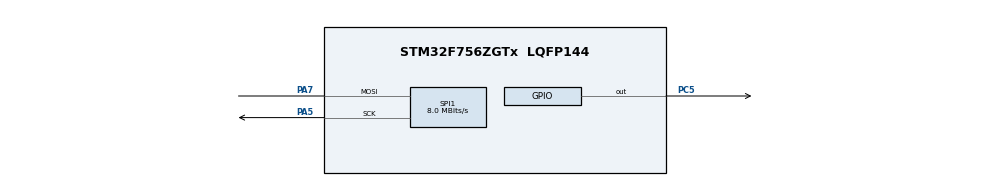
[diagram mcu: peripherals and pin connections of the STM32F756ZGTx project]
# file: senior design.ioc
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CORTEX_M7.default_mode_Activation=1
Mcu.Family=STM32F7
Mcu.Name=STM32F756ZGTx
Mcu.Package=LQFP144
NVIC.PriorityGroup=NVIC_PRIORITYGROUP_4
PA5.Mode=Simplex_Bidirectional_Master
PA5.Signal=SPI1_SCK
PA7.Mode=Simplex_Bidirectional_Master
PA7.Signal=SPI1_MOSI
PC5.Signal=GPIO_Output
ProjectManager.HeapSize=0x200
ProjectManager.StackSize=0x400
ProjectManager.TargetToolchain=STM32CubeIDE
RCC.HSE_VALUE=25000000
RCC.HSI_VALUE=16000000
RCC.LSE_VALUE=32768
RCC.USBFreq_Value=96000000
RCC.VCOOutputFreq_Value=192000000
SPI1.CalculateBaudRate=8.0 MBits/s
SPI1.Direction=SPI_DIRECTION_1LINE
SPI1.Mode=SPI_MODE_MASTER
SPI1.VirtualType=VM_MASTER
board=custom

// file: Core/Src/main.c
/* USER CODE BEGIN Header */
/**
  ******************************************************************************
  * @file           : main.c
  * @brief          : Main program body
  ******************************************************************************
  * @attention
  *
  * Copyright (c) 2025 STMicroelectronics.
  * All rights reserved.
  *
  * This software is licensed under terms that can be found in the LICENSE file
  * in the root directory of this software component.
  * If no LICENSE file comes with this software, it is provided AS-IS.
  *
  ******************************************************************************
  */
/* USER CODE END Header */
#include "main.h"

SPI_HandleTypeDef hspi1;

void SystemClock_Config(void);
static void MPU_Config(void);
static void MX_GPIO_Init(void);
static void MX_SPI1_Init(void);

int main(void)
{

  /* MPU Configuration--------------------------------------------------------*/
  MPU_Config();

  /* MCU Configuration--------------------------------------------------------*/

  /* Reset of all peripherals, Initializes the Flash interface and the Systick. */
  HAL_Init();

  /* Configure the system clock */
  SystemClock_Config();

  /* Initialize all configured peripherals */
  MX_GPIO_Init();
  MX_SPI1_Init();

  /* Infinite loop */
  /* USER CODE BEGIN WHILE */
  HAL_GPIO_WritePin(GPIOC, GPIO_PIN_5, GPIO_PIN_RESET);  // CS low
  HAL_Delay(1);  // wait 1 ms for OLED power to stabilize

   uint16_t cmd;

   // Function Set: 0x38
   cmd = 0x038;
   HAL_GPIO_WritePin(GPIOC, GPIO_PIN_5, GPIO_PIN_RESET);
   HAL_SPI_Transmit(&hspi1, (uint8_t *)&cmd, 1, HAL_MAX_DELAY);
   HAL_GPIO_WritePin(GPIOC, GPIO_PIN_5, GPIO_PIN_SET);

   // Display OFF: 0x08
   cmd = 0x008;
   HAL_GPIO_WritePin(GPIOC, GPIO_PIN_5, GPIO_PIN_RESET);
   HAL_SPI_Transmit(&hspi1, (uint8_t *)&cmd, 1, HAL_MAX_DELAY);
   HAL_GPIO_WritePin(GPIOC, GPIO_PIN_5, GPIO_PIN_SET);

   // Clear Display: 0x01
   cmd = 0x001;
   HAL_GPIO_WritePin(GPIOC, GPIO_PIN_5, GPIO_PIN_RESET);
   HAL_SPI_Transmit(&hspi1, (uint8_t *)&cmd, 1, HAL_MAX_DELAY);
   HAL_GPIO_WritePin(GPIOC, GPIO_PIN_5, GPIO_PIN_SET);
   HAL_Delay(2);

   // Entry Mode Set: 0x06
   cmd = 0x006;
   HAL_GPIO_WritePin(GPIOC, GPIO_PIN_5, GPIO_PIN_RESET);
   HAL_SPI_Transmit(&hspi1, (uint8_t *)&cmd, 1, HAL_MAX_DELAY);
   HAL_GPIO_WritePin(GPIOC, GPIO_PIN_5, GPIO_PIN_SET);

   // Return Home: 0x02
   cmd = 0x002;
   HAL_GPIO_WritePin(GPIOC, GPIO_PIN_5, GPIO_PIN_RESET);
   HAL_SPI_Transmit(&hspi1, (uint8_t *)&cmd, 1, HAL_MAX_DELAY);
   HAL_GPIO_WritePin(GPIOC, GPIO_PIN_5, GPIO_PIN_SET);

   // Display ON: 0x0C
   cmd = 0x00C;
   HAL_GPIO_WritePin(GPIOC, GPIO_PIN_5, GPIO_PIN_RESET);
   HAL_SPI_Transmit(&hspi1, (uint8_t *)&cmd, 1, HAL_MAX_DELAY);
   HAL_GPIO_WritePin(GPIOC, GPIO_PIN_5, GPIO_PIN_SET);

//   // Send data character 'A' → 0x200 + 0x41 = 0x241
//   cmd = 0x242;
//   HAL_GPIO_WritePin(GPIOC, GPIO_PIN_5, GPIO_PIN_RESET);
//   HAL_SPI_Transmit(&hspi1, (uint8_t *)&cmd, 1, HAL_MAX_DELAY);
//   HAL_GPIO_WritePin(GPIOC, GPIO_PIN_5, GPIO_PIN_SET);

   const char *msg = "blindspot2";
   for (int i = 0; msg[i] != '\0'; i++) {
       cmd = 0x200 + msg[i];  // Add 0x200 to mark as data
       HAL_GPIO_WritePin(GPIOC, GPIO_PIN_5, GPIO_PIN_RESET); // CS low
       HAL_SPI_Transmit(&hspi1, (uint8_t *)&cmd, 1, HAL_MAX_DELAY);
       HAL_GPIO_WritePin(GPIOC, GPIO_PIN_5, GPIO_PIN_SET);   // CS high
       HAL_Delay(2); // small delay between chars
   }

  while (1)
  {
    /* USER CODE END WHILE */

  }
}

void SystemClock_Config(void)
{
  RCC_OscInitTypeDef RCC_OscInitStruct = {0};
  RCC_ClkInitTypeDef RCC_ClkInitStruct = {0};

  /** Configure the main internal regulator output voltage
  */
  __HAL_RCC_PWR_CLK_ENABLE();
  __HAL_PWR_VOLTAGESCALING_CONFIG(PWR_REGULATOR_VOLTAGE_SCALE3);

  /** Initializes the RCC Oscillators according to the specified parameters
  * in the RCC_OscInitTypeDef structure.
  */
  RCC_OscInitStruct.OscillatorType = RCC_OSCILLATORTYPE_HSI;
  RCC_OscInitStruct.HSIState = RCC_HSI_ON;
  RCC_OscInitStruct.HSICalibrationValue = RCC_HSICALIBRATION_DEFAULT;
  RCC_OscInitStruct.PLL.PLLState = RCC_PLL_NONE;
  if (HAL_RCC_OscConfig(&RCC_OscInitStruct) != HAL_OK)
  {
    Error_Handler();
  }

  /** Initializes the CPU, AHB and APB buses clocks
  */
  RCC_ClkInitStruct.ClockType = RCC_CLOCKTYPE_HCLK|RCC_CLOCKTYPE_SYSCLK
                              |RCC_CLOCKTYPE_PCLK1|RCC_CLOCKTYPE_PCLK2;
  RCC_ClkInitStruct.SYSCLKSource = RCC_SYSCLKSOURCE_HSI;
  RCC_ClkInitStruct.AHBCLKDivider = RCC_SYSCLK_DIV1;
  RCC_ClkInitStruct.APB1CLKDivider = RCC_HCLK_DIV1;
  RCC_ClkInitStruct.APB2CLKDivider = RCC_HCLK_DIV1;

  if (HAL_RCC_ClockConfig(&RCC_ClkInitStruct, FLASH_LATENCY_0) != HAL_OK)
  {
    Error_Handler();
  }
}

static void MX_SPI1_Init(void)
{

  /* SPI1 parameter configuration*/
  hspi1.Instance = SPI1;
  hspi1.Init.Mode = SPI_MODE_MASTER;
  hspi1.Init.Direction = SPI_DIRECTION_1LINE;
  hspi1.Init.DataSize = SPI_DATASIZE_10BIT;
  hspi1.Init.CLKPolarity = SPI_POLARITY_LOW;
  hspi1.Init.CLKPhase = SPI_PHASE_1EDGE;
  hspi1.Init.NSS = SPI_NSS_SOFT;
  hspi1.Init.BaudRatePrescaler = SPI_BAUDRATEPRESCALER_2;
  hspi1.Init.FirstBit = SPI_FIRSTBIT_MSB;
  hspi1.Init.TIMode = SPI_TIMODE_DISABLE;
  hspi1.Init.CRCCalculation = SPI_CRCCALCULATION_DISABLE;
  hspi1.Init.CRCPolynomial = 7;
  hspi1.Init.CRCLength = SPI_CRC_LENGTH_DATASIZE;
  hspi1.Init.NSSPMode = SPI_NSS_PULSE_ENABLE;
  if (HAL_SPI_Init(&hspi1) != HAL_OK)
  {
    Error_Handler();
  }

}

static void MX_GPIO_Init(void)
{
  GPIO_InitTypeDef GPIO_InitStruct = {0};

  /* GPIO Ports Clock Enable */
  __HAL_RCC_GPIOA_CLK_ENABLE();
  __HAL_RCC_GPIOC_CLK_ENABLE();

  /*Configure GPIO pin Output Level */
  HAL_GPIO_WritePin(GPIOC, GPIO_PIN_5, GPIO_PIN_RESET);

  /*Configure GPIO pin : PC5 */
  GPIO_InitStruct.Pin = GPIO_PIN_5;
  GPIO_InitStruct.Mode = GPIO_MODE_OUTPUT_PP;
  GPIO_InitStruct.Pull = GPIO_NOPULL;
  GPIO_InitStruct.Speed = GPIO_SPEED_FREQ_LOW;
  HAL_GPIO_Init(GPIOC, &GPIO_InitStruct);

}

 /* MPU Configuration */

void MPU_Config(void)
{
  MPU_Region_InitTypeDef MPU_InitStruct = {0};

  /* Disables the MPU */
  HAL_MPU_Disable();

  /** Initializes and configures the Region and the memory to be protected
  */
  MPU_InitStruct.Enable = MPU_REGION_ENABLE;
  MPU_InitStruct.Number = MPU_REGION_NUMBER0;
  MPU_InitStruct.BaseAddress = 0x0;
  MPU_InitStruct.Size = MPU_REGION_SIZE_4GB;
  MPU_InitStruct.SubRegionDisable = 0x87;
  MPU_InitStruct.TypeExtField = MPU_TEX_LEVEL0;
  MPU_InitStruct.AccessPermission = MPU_REGION_NO_ACCESS;
  MPU_InitStruct.DisableExec = MPU_INSTRUCTION_ACCESS_DISABLE;
  MPU_InitStruct.IsShareable = MPU_ACCESS_SHAREABLE;
  MPU_InitStruct.IsCacheable = MPU_ACCESS_NOT_CACHEABLE;
  MPU_InitStruct.IsBufferable = MPU_ACCESS_NOT_BUFFERABLE;

  HAL_MPU_ConfigRegion(&MPU_InitStruct);
  /* Enables the MPU */
  HAL_MPU_Enable(MPU_PRIVILEGED_DEFAULT);

}

void Error_Handler(void)
{
  __disable_irq();
  while (1)
  {
  }
}
